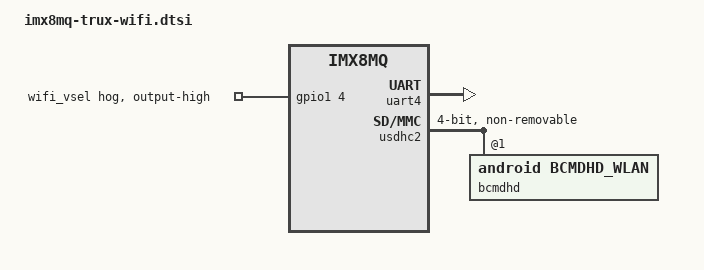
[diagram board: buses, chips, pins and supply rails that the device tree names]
// SPDX-License-Identifier: (GPL-2.0 OR MIT)
/*
 * Copyright 2017 NXP
 * Copyright 2022 Trucrux
 */

/* Set WIFI SDIO voltage at 1.8V */
&gpio1 {
	wifi_vsel_hog {
		gpio-hog;
		gpios = <4 0>;
		output-high;
		line-name = "wifi_vsel";
	};
};

/* Bluetooth */
&uart4 {
	status = "okay";
};

/* WIFI */
&usdhc2 {
	#address-cells = <1>;
	#size-cells = <0>;
	pinctrl-names = "default";
	pinctrl-0 = <&pinctrl_usdhc2>, <&pinctrl_wifi>;
	bus-width = <4>;
	non-removable;
	keep-power-in-suspend;
	status = "okay";

	bcmdhd: bcmdhd@1 {
		reg = <1>;
		compatible = "android,bcmdhd_wlan";
		bcmdhd_fw = "/lib/firmware/bcmdhd/fw_bcm43752a2_ag.bin";
		bcmdhd_nv = "/lib/firmware/bcmdhd/nvram_ap6275s.txt";
	};
};
